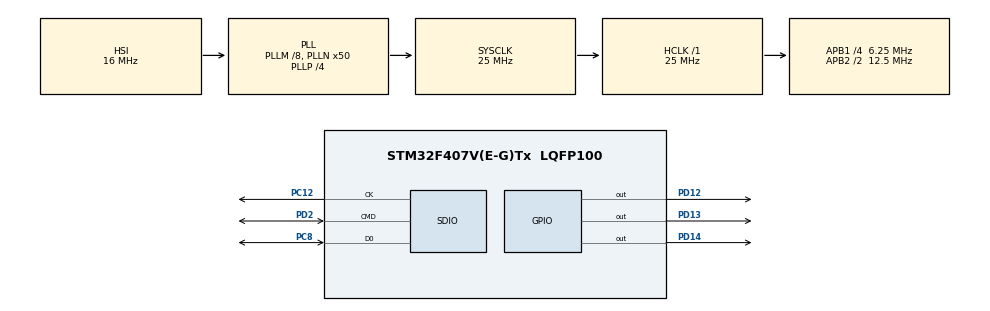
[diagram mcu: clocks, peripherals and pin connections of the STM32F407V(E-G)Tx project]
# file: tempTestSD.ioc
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FATFS.USE_DMA_CODE_SD=0
FATFS._MAX_SS=4096
Mcu.Family=STM32F4
Mcu.Name=STM32F407V(E-G)Tx
Mcu.Package=LQFP100
NVIC.PriorityGroup=NVIC_PRIORITYGROUP_4
NVIC.SDIO_IRQn=true\:0\:0\:false\:false\:true\:true\:true
PC12.Mode=SD_1_bit
PC12.Signal=SDIO_CK
PC8.Mode=SD_1_bit
PC8.Signal=SDIO_D0
PD12.Signal=GPIO_Output
PD13.Signal=GPIO_Output
PD14.Signal=GPIO_Output
PD2.Mode=SD_1_bit
PD2.Signal=SDIO_CMD
ProjectManager.HeapSize=0x2000
ProjectManager.StackSize=0x4000
ProjectManager.TargetToolchain=SW4STM32
RCC.48MHZClocksFreq_Value=14285714.285714285
RCC.AHBFreq_Value=25000000
RCC.APB1CLKDivider=RCC_HCLK_DIV4
RCC.APB1Freq_Value=6250000
RCC.APB1TimFreq_Value=12500000
RCC.APB2CLKDivider=RCC_HCLK_DIV2
RCC.APB2Freq_Value=12500000
RCC.APB2TimFreq_Value=25000000
RCC.CortexFreq_Value=25000000
RCC.HCLKFreq_Value=25000000
RCC.HSE_VALUE=8000000
RCC.HSI_VALUE=16000000
RCC.LSE_VALUE=32768
RCC.PLLM=8
RCC.PLLN=50
RCC.PLLP=RCC_PLLP_DIV4
RCC.PLLQ=7
RCC.SYSCLKFreq_VALUE=25000000
RCC.SYSCLKSource=RCC_SYSCLKSOURCE_PLLCLK
RCC.VCOOutputFreq_Value=100000000
SDIO.ClockDiv=0
VP_FATFS_VS_SDIO.Mode=SDIO
board=STM32F4DISCOVERY

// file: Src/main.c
/* USER CODE BEGIN Header */
/**
  ******************************************************************************
  * @file           : main.c
  * @brief          : Main program body
  ******************************************************************************
  * @attention
  *
  * <h2><center>&copy; Copyright (c) 2019 STMicroelectronics.
  * All rights reserved.</center></h2>
  *
  * This software component is licensed by ST under Ultimate Liberty license
  * SLA0044, the "License"; You may not use this file except in compliance with
  * the License. You may obtain a copy of the License at:
  *                             www.st.com/SLA0044
  *
  ******************************************************************************
  */
/* USER CODE END Header */

#include "main.h"
#include "fatfs.h"

SD_HandleTypeDef hsd;

void SystemClock_Config(void);
static void MX_GPIO_Init(void);
static void MX_SDIO_SD_Init(void);

int main(void)
{

  /* MCU Configuration--------------------------------------------------------*/

  /* Reset of all peripherals, Initializes the Flash interface and the Systick. */
  HAL_Init();

  /* Configure the system clock */
  SystemClock_Config();

  /* Initialize all configured peripherals */
  MX_GPIO_Init();
  MX_SDIO_SD_Init();
  MX_FATFS_Init();
  /* USER CODE BEGIN 2 */

  FATFS myFS;

  if(f_mount(&myFS, SDPath, 1)==FR_OK) // here we mount a SDcard
  {

		FIL m_filePointer;
		UINT testByte;
		f_open(&m_filePointer, "LOG.TXT" , FA_OPEN_APPEND | FA_WRITE | FA_OPEN_ALWAYS); // LOG.TXT will be created in LOG file
		f_write(&m_filePointer, "Hello from chandramohan\n\r", 10, &testByte);
		f_close(&m_filePointer);
  }
  else
  {
	  HAL_GPIO_TogglePin(GPIOD,GPIO_PIN_14);
  }
  /* USER CODE END 2 */

  /* Infinite loop */
  while (1)
  {

  }
}

void SystemClock_Config(void)
{
  RCC_OscInitTypeDef RCC_OscInitStruct = {0};
  RCC_ClkInitTypeDef RCC_ClkInitStruct = {0};

  /** Configure the main internal regulator output voltage
  */
  __HAL_RCC_PWR_CLK_ENABLE();
  __HAL_PWR_VOLTAGESCALING_CONFIG(PWR_REGULATOR_VOLTAGE_SCALE1);
  /** Initializes the CPU, AHB and APB busses clocks
  */
  RCC_OscInitStruct.OscillatorType = RCC_OSCILLATORTYPE_HSI;
  RCC_OscInitStruct.HSIState = RCC_HSI_ON;
  RCC_OscInitStruct.HSICalibrationValue = RCC_HSICALIBRATION_DEFAULT;
  RCC_OscInitStruct.PLL.PLLState = RCC_PLL_ON;
  RCC_OscInitStruct.PLL.PLLSource = RCC_PLLSOURCE_HSI;
  RCC_OscInitStruct.PLL.PLLM = 8;
  RCC_OscInitStruct.PLL.PLLN = 50;
  RCC_OscInitStruct.PLL.PLLP = RCC_PLLP_DIV4;
  RCC_OscInitStruct.PLL.PLLQ = 7;
  if (HAL_RCC_OscConfig(&RCC_OscInitStruct) != HAL_OK)
  {
    Error_Handler();
  }
  /** Initializes the CPU, AHB and APB busses clocks
  */
  RCC_ClkInitStruct.ClockType = RCC_CLOCKTYPE_HCLK|RCC_CLOCKTYPE_SYSCLK
                              |RCC_CLOCKTYPE_PCLK1|RCC_CLOCKTYPE_PCLK2;
  RCC_ClkInitStruct.SYSCLKSource = RCC_SYSCLKSOURCE_PLLCLK;
  RCC_ClkInitStruct.AHBCLKDivider = RCC_SYSCLK_DIV1;
  RCC_ClkInitStruct.APB1CLKDivider = RCC_HCLK_DIV4;
  RCC_ClkInitStruct.APB2CLKDivider = RCC_HCLK_DIV2;

  if (HAL_RCC_ClockConfig(&RCC_ClkInitStruct, FLASH_LATENCY_0) != HAL_OK)
  {
    Error_Handler();
  }
}

static void MX_SDIO_SD_Init(void)
{

  hsd.Instance = SDIO;
  hsd.Init.ClockEdge = SDIO_CLOCK_EDGE_RISING;
  hsd.Init.ClockBypass = SDIO_CLOCK_BYPASS_DISABLE;
  hsd.Init.ClockPowerSave = SDIO_CLOCK_POWER_SAVE_DISABLE;
  hsd.Init.BusWide = SDIO_BUS_WIDE_1B;
  hsd.Init.HardwareFlowControl = SDIO_HARDWARE_FLOW_CONTROL_DISABLE;
  hsd.Init.ClockDiv = 0;

}

static void MX_GPIO_Init(void)
{
  GPIO_InitTypeDef GPIO_InitStruct = {0};

  /* GPIO Ports Clock Enable */
  __HAL_RCC_GPIOD_CLK_ENABLE();
  __HAL_RCC_GPIOC_CLK_ENABLE();

  /*Configure GPIO pin Output Level */
  HAL_GPIO_WritePin(GPIOD, GPIO_PIN_12|GPIO_PIN_13|GPIO_PIN_14, GPIO_PIN_RESET);

  /*Configure GPIO pins : PD12 PD13 PD14 */
  GPIO_InitStruct.Pin = GPIO_PIN_12|GPIO_PIN_13|GPIO_PIN_14;
  GPIO_InitStruct.Mode = GPIO_MODE_OUTPUT_PP;
  GPIO_InitStruct.Pull = GPIO_NOPULL;
  GPIO_InitStruct.Speed = GPIO_SPEED_FREQ_LOW;
  HAL_GPIO_Init(GPIOD, &GPIO_InitStruct);

}

void Error_Handler(void)
{
}

/************************ (C) COPYRIGHT STMicroelectronics *****END OF FILE****/
